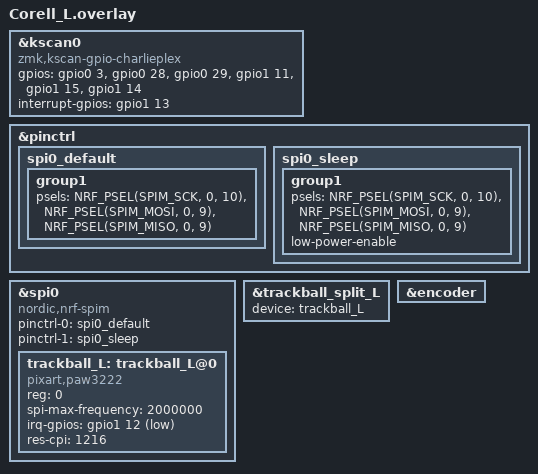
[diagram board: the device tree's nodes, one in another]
#include "corell.dtsi"
#include <dt-bindings/pinctrl/nrf-pinctrl.h>
#include <dt-bindings/zmk/input_transform.h>
#include <input/processors.dtsi>

&kscan0 {
    compatible = "zmk,kscan-gpio-charlieplex";
    gpios
        = <&gpio0 3 (GPIO_ACTIVE_HIGH)>
        , <&gpio0 28 (GPIO_ACTIVE_HIGH)>
        , <&gpio0 29 (GPIO_ACTIVE_HIGH)>
        , <&gpio1 11 (GPIO_ACTIVE_HIGH)>
        , <&gpio1 15 (GPIO_ACTIVE_HIGH)>
        , <&gpio1 14 (GPIO_ACTIVE_HIGH)>
        ;
    interrupt-gpios = <&gpio1 13 (GPIO_ACTIVE_HIGH | GPIO_PULL_DOWN)>;
};

&pinctrl {
    spi0_default: spi0_default {
        group1 {
            psels = <NRF_PSEL(SPIM_SCK, 0, 10)>,
                    <NRF_PSEL(SPIM_MOSI, 0, 9)>,
                    <NRF_PSEL(SPIM_MISO, 0, 9)>;
        };
    };

    spi0_sleep: spi0_sleep {
        group1 {
            psels = <NRF_PSEL(SPIM_SCK, 0, 10)>,
                    <NRF_PSEL(SPIM_MOSI, 0, 9)>,
                    <NRF_PSEL(SPIM_MISO, 0, 9)>;
            low-power-enable;
        };
    };
};

&spi0 {
    status = "okay";
    compatible = "nordic,nrf-spim";
    pinctrl-0 = <&spi0_default>;
    pinctrl-1 = <&spi0_sleep>;
    pinctrl-names = "default", "sleep";

    trackball_L: trackball_L@0 {
        compatible = "pixart,paw3222";
        reg = <0>;
        status = "okay";
        spi-max-frequency = <2000000>;
        irq-gpios = <&gpio1 12 (GPIO_ACTIVE_LOW | GPIO_PULL_UP)>;
        res-cpi = <1216>;
    };
};

&trackball_split_L {
    device = <&trackball_L>;
};

&encoder {
    status = "okay";
};
